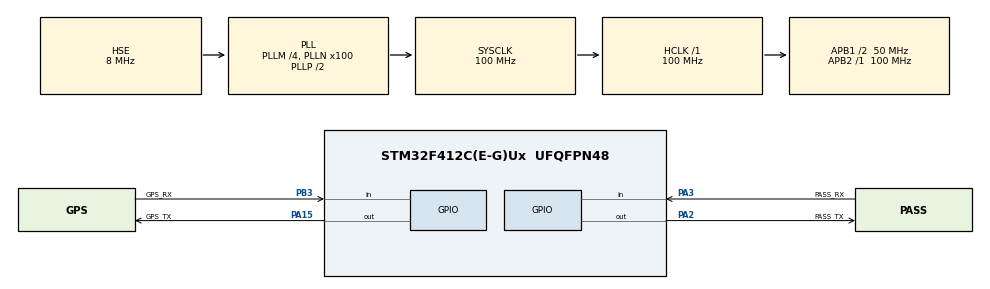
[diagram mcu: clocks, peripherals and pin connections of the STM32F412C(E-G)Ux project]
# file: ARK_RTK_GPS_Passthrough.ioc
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Mcu.Family=STM32F4
Mcu.Name=STM32F412C(E-G)Ux
Mcu.Package=UFQFPN48
NVIC.PriorityGroup=NVIC_PRIORITYGROUP_4
PA13.Mode=Serial_Wire
PA13.Signal=SYS_JTMS-SWDIO
PA14.Mode=Serial_Wire
PA14.Signal=SYS_JTCK-SWCLK
PA15.GPIO_Label=GPS_TX
PA15.Signal=GPIO_Output
PA2.GPIO_Label=PASS_TX
PA2.Signal=GPIO_Output
PA3.GPIO_Label=PASS_RX
PA3.Signal=GPIO_Input
PB3.GPIO_Label=GPS_RX
PB3.Signal=GPIO_Input
PH0\ -\ OSC_IN.Mode=HSE-External-Oscillator
PH0\ -\ OSC_IN.Signal=RCC_OSC_IN
PH1\ -\ OSC_OUT.Mode=HSE-External-Oscillator
PH1\ -\ OSC_OUT.Signal=RCC_OSC_OUT
ProjectManager.HeapSize=0x200
ProjectManager.StackSize=0x400
ProjectManager.TargetToolchain=Makefile
RCC.AHBFreq_Value=100000000
RCC.APB1CLKDivider=RCC_HCLK_DIV2
RCC.APB1Freq_Value=50000000
RCC.APB1TimFreq_Value=100000000
RCC.APB2Freq_Value=100000000
RCC.APB2TimFreq_Value=100000000
RCC.CortexFreq_Value=100000000
RCC.HCLKFreq_Value=100000000
RCC.HSE_VALUE=8000000
RCC.PLLM=4
RCC.PLLN=100
RCC.PLLSourceVirtual=RCC_PLLSOURCE_HSE
RCC.SYSCLKFreq_VALUE=100000000
RCC.SYSCLKSource=RCC_SYSCLKSOURCE_PLLCLK
RCC.USBFreq_Value=100000000
RCC.VCOOutputFreq_Value=200000000
board=custom

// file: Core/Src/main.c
/* USER CODE BEGIN Header */
/**
  ******************************************************************************
  * @file           : main.c
  * @brief          : Main program body
  ******************************************************************************
  * @attention
  *
  * <h2><center>&copy; Copyright (c) 2021 STMicroelectronics.
  * All rights reserved.</center></h2>
  *
  * This software component is licensed by ST under BSD 3-Clause license,
  * the "License"; You may not use this file except in compliance with the
  * License. You may obtain a copy of the License at:
  *                        opensource.org/licenses/BSD-3-Clause
  *
  ******************************************************************************
  */
/* USER CODE END Header */
#include "main.h"

/* USER CODE BEGIN PV */

// #define CIRC_BUF_SZ       24576  /* must be power of two */

// static uint8_t uart1_rx_dma_circ_buf[CIRC_BUF_SZ];
// static uint32_t uart1_rd_ptr;

// #define UART1_DMA_WRITE_PTR ((CIRC_BUF_SZ - huart1.hdmarx->Instance->NDTR) & (CIRC_BUF_SZ - 1))

// static uint8_t uart2_rx_dma_circ_buf[CIRC_BUF_SZ];
// static uint32_t uart2_rd_ptr;

// #define UART2_DMA_WRITE_PTR ((CIRC_BUF_SZ - huart2.hdmarx->Instance->NDTR) & (CIRC_BUF_SZ - 1))

/* USER CODE END PV */

void SystemClock_Config(void);
static void MX_GPIO_Init(void);

int main(void)
{

  /* MCU Configuration--------------------------------------------------------*/

  /* Reset of all peripherals, Initializes the Flash interface and the Systick. */
  HAL_Init();

  /* Configure the system clock */
  SystemClock_Config();

  /* Initialize all configured peripherals */
  MX_GPIO_Init();

  /* Infinite loop */
  /* USER CODE BEGIN WHILE */
  while (1)
  {
    HAL_GPIO_WritePin(PASS_TX_GPIO_Port, PASS_TX_Pin, HAL_GPIO_ReadPin(GPS_RX_GPIO_Port, GPS_RX_Pin));
    HAL_GPIO_WritePin(GPS_TX_GPIO_Port, GPS_TX_Pin, HAL_GPIO_ReadPin(PASS_RX_GPIO_Port, PASS_RX_Pin));
    /* USER CODE END WHILE */

    /* USER CODE BEGIN 3 */
  }
  return 1;
  /* USER CODE END 3 */
}

void SystemClock_Config(void)
{
  RCC_OscInitTypeDef RCC_OscInitStruct = {0};
  RCC_ClkInitTypeDef RCC_ClkInitStruct = {0};

  /** Configure the main internal regulator output voltage
  */
  __HAL_RCC_PWR_CLK_ENABLE();
  __HAL_PWR_VOLTAGESCALING_CONFIG(PWR_REGULATOR_VOLTAGE_SCALE1);
  /** Initializes the RCC Oscillators according to the specified parameters
  * in the RCC_OscInitTypeDef structure.
  */
  RCC_OscInitStruct.OscillatorType = RCC_OSCILLATORTYPE_HSE;
  RCC_OscInitStruct.HSEState = RCC_HSE_ON;
  RCC_OscInitStruct.PLL.PLLState = RCC_PLL_ON;
  RCC_OscInitStruct.PLL.PLLSource = RCC_PLLSOURCE_HSE;
  RCC_OscInitStruct.PLL.PLLM = 4;
  RCC_OscInitStruct.PLL.PLLN = 100;
  RCC_OscInitStruct.PLL.PLLP = RCC_PLLP_DIV2;
  RCC_OscInitStruct.PLL.PLLQ = 2;
  RCC_OscInitStruct.PLL.PLLR = 2;
  if (HAL_RCC_OscConfig(&RCC_OscInitStruct) != HAL_OK)
  {
    Error_Handler();
  }
  /** Initializes the CPU, AHB and APB buses clocks
  */
  RCC_ClkInitStruct.ClockType = RCC_CLOCKTYPE_HCLK|RCC_CLOCKTYPE_SYSCLK
                              |RCC_CLOCKTYPE_PCLK1|RCC_CLOCKTYPE_PCLK2;
  RCC_ClkInitStruct.SYSCLKSource = RCC_SYSCLKSOURCE_PLLCLK;
  RCC_ClkInitStruct.AHBCLKDivider = RCC_SYSCLK_DIV1;
  RCC_ClkInitStruct.APB1CLKDivider = RCC_HCLK_DIV2;
  RCC_ClkInitStruct.APB2CLKDivider = RCC_HCLK_DIV1;

  if (HAL_RCC_ClockConfig(&RCC_ClkInitStruct, FLASH_LATENCY_3) != HAL_OK)
  {
    Error_Handler();
  }
}

static void MX_GPIO_Init(void)
{
  GPIO_InitTypeDef GPIO_InitStruct = {0};

  /* GPIO Ports Clock Enable */
  __HAL_RCC_GPIOH_CLK_ENABLE();
  __HAL_RCC_GPIOA_CLK_ENABLE();
  __HAL_RCC_GPIOB_CLK_ENABLE();

  /*Configure GPIO pin Output Level */
  HAL_GPIO_WritePin(GPIOA, PASS_TX_Pin|GPS_TX_Pin, GPIO_PIN_RESET);

  /*Configure GPIO pins : PASS_TX_Pin GPS_TX_Pin */
  GPIO_InitStruct.Pin = PASS_TX_Pin|GPS_TX_Pin;
  GPIO_InitStruct.Mode = GPIO_MODE_OUTPUT_PP;
  GPIO_InitStruct.Pull = GPIO_NOPULL;
  GPIO_InitStruct.Speed = GPIO_SPEED_FREQ_LOW;
  HAL_GPIO_Init(GPIOA, &GPIO_InitStruct);

  /*Configure GPIO pin : PASS_RX_Pin */
  GPIO_InitStruct.Pin = PASS_RX_Pin;
  GPIO_InitStruct.Mode = GPIO_MODE_INPUT;
  GPIO_InitStruct.Pull = GPIO_NOPULL;
  HAL_GPIO_Init(PASS_RX_GPIO_Port, &GPIO_InitStruct);

  /*Configure GPIO pin : GPS_RX_Pin */
  GPIO_InitStruct.Pin = GPS_RX_Pin;
  GPIO_InitStruct.Mode = GPIO_MODE_INPUT;
  GPIO_InitStruct.Pull = GPIO_NOPULL;
  HAL_GPIO_Init(GPS_RX_GPIO_Port, &GPIO_InitStruct);

}

void Error_Handler(void)
{
  __disable_irq();
  while (1)
  {
  }
}

/************************ (C) COPYRIGHT STMicroelectronics *****END OF FILE****/
